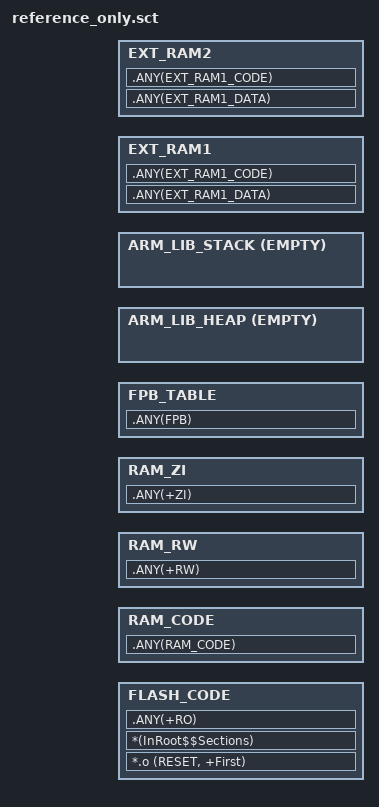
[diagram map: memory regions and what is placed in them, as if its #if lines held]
#! armcc -E -I "D:\CODEX\sos-card\tools\ota\gr_boot\Src\user" -I "D:\CODEX\sos-card\tools\ota\gr_boot\Src\config" -I "D:\CODEX\sos-card\SDK\platform\soc\linker\keil" --cpu Cortex-M4

; SAM | 2026-10-20 20:05 +08:00 | Rebase isolated reference preprocessing includes; preserve vendor layout.
#include "flash_scatter_config.h"
#define ALIGN_DWORD 0x0008
#define ALIGN_WORD  0x0004
#define ALIGN_16KB  0x4000
#define ALIGN_32KB  0x8000

; *************************************************************
; *** Scatter-Loading Description File generated by uVision ***
; *************************************************************
;
; If an application uses a different memory layout then it must
; use a customized scatter file.
;**************************************************************

; SAM | 2026-10-21 09:35 +08:00 | Hard link cap: candidate Boot must fit 36KiB before scratch.
; SAM | 2026-10-23 +08:00 | Undeployed 40KiB candidate budget; A/B and NVDS unchanged.
LR_FLASH APP_CODE_RUN_ADDR 0xA000 {

    ; Flash AREA
    FLASH_CODE APP_CODE_RUN_ADDR APP_MAX_CODE_SIZE {  ; load address = execution address
        *.o (RESET, +First)
        *(InRoot$$Sections)
        .ANY(+RO)
      }

    #if defined(XIP_MODE)
    ; Ram code space AREA
    RAM_CODE (RAM_CODE_SPACE_START) {
        .ANY(RAM_CODE)
    }
    #endif

    #if defined(HMIRROR_MODE)
    ; Ram data
    RAM_RW (+0) APP_RAM_SIZE {
        .ANY(+RW)
    }
    RAM_ZI (+0) APP_RAM_SIZE {
        .ANY(+ZI)
    }
    #else
    ; Ram data
    RAM_RW (+HIGH_RAM_OFFSET) APP_RAM_SIZE {
        .ANY(+RW)
    }
    RAM_ZI (+0) APP_RAM_SIZE {
        .ANY(+ZI)
    }
    #endif

    ; FPB space
    FPB_TABLE AlignExpr(+0, 128) FPB_DATA_SPACE_SIZE {
        .ANY(FPB)
    }

    ; Ram heap
    ARM_LIB_HEAP  AlignExpr(STACK_END_ADDR - SYSTEM_STACK_SIZE - SYSTEM_HEAP_SIZE, ALIGN_DWORD) EMPTY SYSTEM_HEAP_SIZE {}
    ; Ram stack
    ARM_LIB_STACK AlignExpr(STACK_END_ADDR, ALIGN_DWORD) EMPTY -SYSTEM_STACK_SIZE {}

    ; extern ram use for psram
    EXT_RAM1 (EXT_RAM1_STRAT_ADDR) APP_EXT_RAM1_SIZE {
        .ANY(EXT_RAM1_DATA)
        .ANY(EXT_RAM1_CODE)
    }
    EXT_RAM2 (EXT_RAM2_STRAT_ADDR) APP_EXT_RAM2_SIZE {
        .ANY(EXT_RAM1_DATA)
        .ANY(EXT_RAM1_CODE)
    }
}
